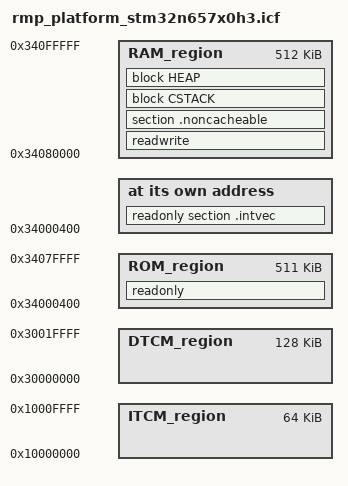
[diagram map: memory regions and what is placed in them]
/*###ICF### Section handled by ICF editor, don't touch! ****/
/*-Editor annotation file-*/
/* IcfEditorFile="$TOOLKIT_DIR$\config\ide\IcfEditor\cortex_v1_0.xml" */
/*-Specials-*/
define symbol __ICFEDIT_intvec_start__ = 0x34000400;
/*-Memory Regions-*/
/* The STM32N6 has no internal flash: the whole image runs from the secure
   alias of FLEXRAM/AXISRAM1 and is downloaded by the debugger. The region end
   is kept at the top of AXISRAM1 (0x34100000) to stay clear of the unpowered
   AXISRAM3 block at 0x34200000, which hangs the AXI matrix when touched. */
define symbol __ICFEDIT_region_ROM_start__ = 0x34000400;
define symbol __ICFEDIT_region_ROM_end__   = 0x3407FFFF;
define symbol __ICFEDIT_region_RAM_start__ = 0x34080000;
define symbol __ICFEDIT_region_RAM_end__   = 0x340FFFFF;
/*-Sizes-*/
define symbol __ICFEDIT_size_cstack__ = 0x1000;
define symbol __ICFEDIT_size_heap__   = 0x400;
/**** End of ICF editor section. ###ICF###*/

define symbol __region_ITCM_start__  = 0x10000000;
define symbol __region_ITCM_end__    = 0x1000FFFF;
define symbol __region_DTCM_start__  = 0x30000000;
define symbol __region_DTCM_end__    = 0x3001FFFF;

define memory mem with size = 4G;
define region ROM_region      = mem:[from __ICFEDIT_region_ROM_start__ to __ICFEDIT_region_ROM_end__];
define region RAM_region      = mem:[from __ICFEDIT_region_RAM_start__ to __ICFEDIT_region_RAM_end__];
define region ITCM_region     = mem:[from __region_ITCM_start__ to __region_ITCM_end__];
define region DTCM_region     = mem:[from __region_DTCM_start__ to __region_DTCM_end__];

define block CSTACK    with alignment = 8, size = __ICFEDIT_size_cstack__   { };
define block HEAP      with alignment = 8, size = __ICFEDIT_size_heap__     { };

initialize by copy { readwrite };
do not initialize  { section .noinit };

place at address mem:__ICFEDIT_intvec_start__ { readonly section .intvec };

place in ROM_region   { readonly };
place in RAM_region   { readwrite, section .noncacheable,
                        block CSTACK, block HEAP };
